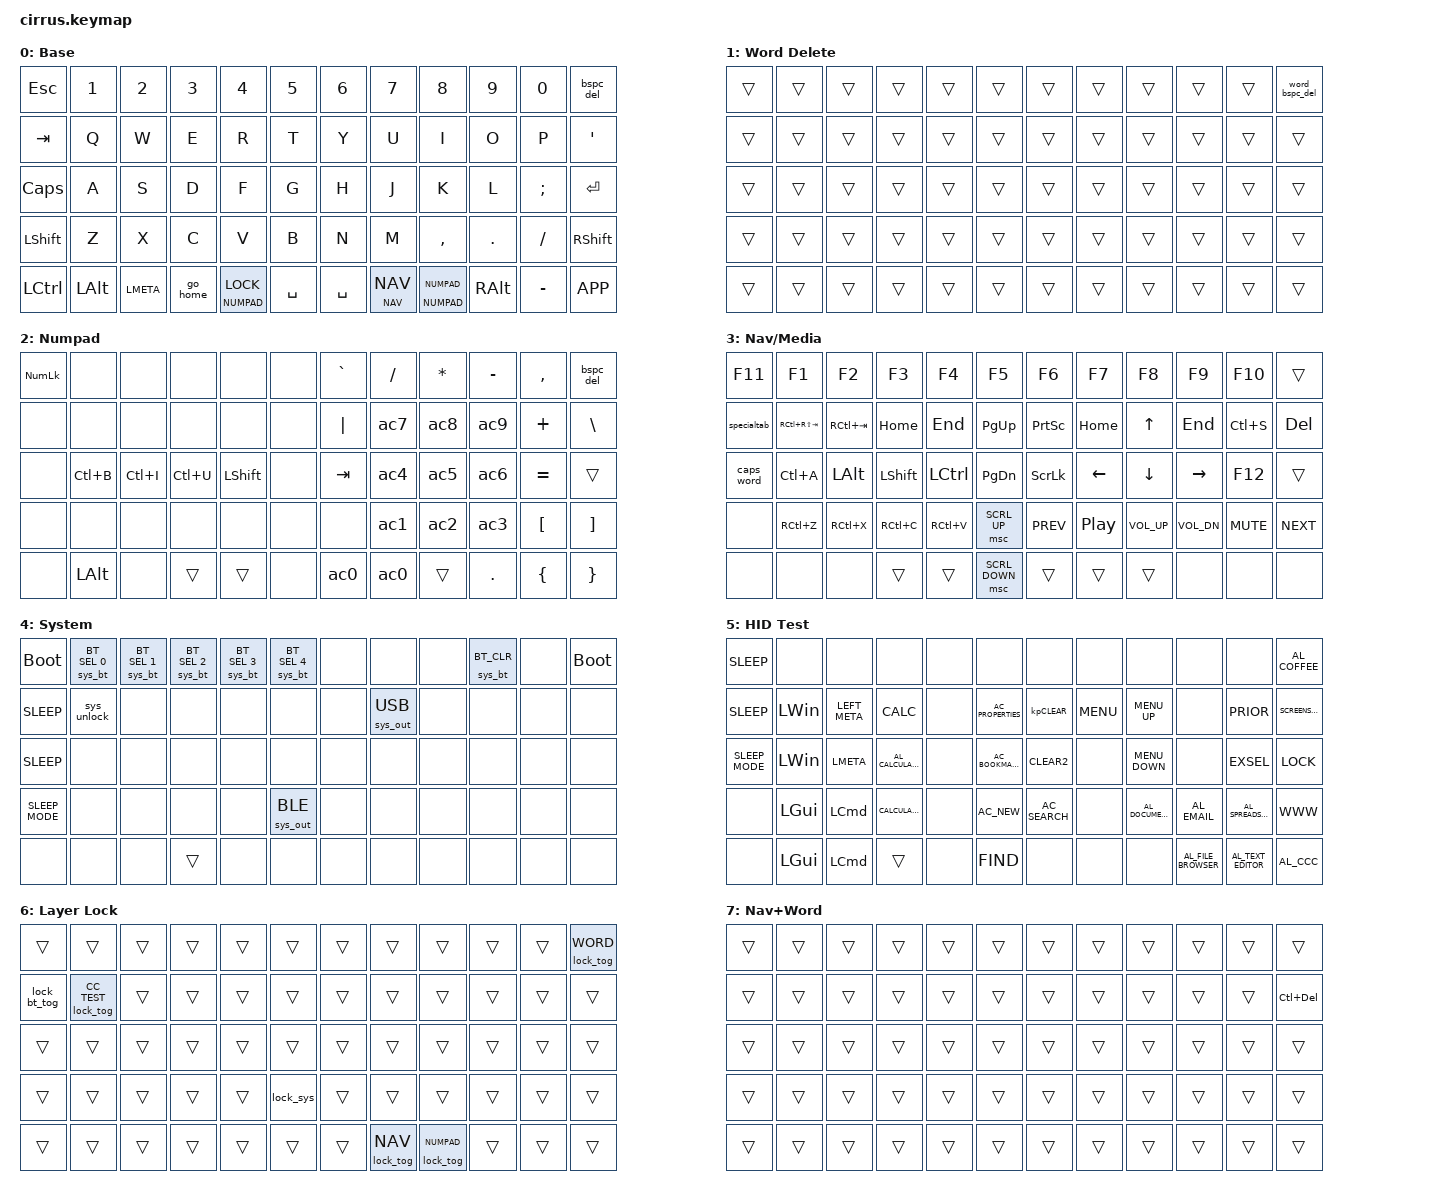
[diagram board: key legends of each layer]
#include <behaviors.dtsi>
#include <dt-bindings/zmk/bt.h>
#include <dt-bindings/zmk/keys.h>
#include <dt-bindings/zmk/outputs.h>
#include <dt-bindings/zmk/pointing.h>

// Layer numbers, by name. Use these names (not raw numbers) in bindings below,
// so adding or reordering layers can't silently break a key.
// Higher numbers sit "on top": their keys win over lower layers.
#define BASE      0
#define WORD      1   // word-delete mode (toggled on/off; sits just above Base)
#define NUMPAD    2
#define NAV       3
#define SYS       4
#define CC_TEST   5
#define LOCK      6
#define NAV_WORD  7   // turns on automatically when Nav + Word are both on

// Numpad digit that types a normal digit, but a KEYPAD digit while Alt is held, so Windows
// Alt codes work (hold Alt, type e.g. 0176, let go of Alt: °). Alt stays held (keep-mods).
// (MOD_MORPH_0 holds the "#binding-cells" line: a "#" can't appear directly inside ALT_CODE_DIGIT)
#define MOD_MORPH_0 compatible = "zmk,behavior-mod-morph"; #binding-cells = <0>
#define ALT_CODE_DIGIT(node, n) \
    node: node { \
        MOD_MORPH_0; \
        display-name = "Digit (Alt: keypad)"; \
        bindings = <&kp N##n>, <&kp KP_N##n>; \
        mods = <(MOD_LALT|MOD_RALT)>; \
        keep-mods = <(MOD_LALT|MOD_RALT)>; \
    };

/ {
    macros {
        // Hold Alt and tap Tab (Alt+Tab window switcher); Alt is released when you let go
        specialtab: specialtab {
            display-name = "Alt-Tab Hold";
            compatible = "zmk,behavior-macro";
            #binding-cells = <0>;
            bindings =
                <&macro_press>,
                <&kp LEFT_ALT>,
                <&macro_tap>,
                <&kp LA(TAB)>,
                <&macro_pause_for_release>,
                <&macro_release>,
                <&kp LEFT_ALT>;
        };

        // "Go home": turn off every locked layer and return to normal typing,
        // but leave word-delete mode as it was.
        go_home: go_home {
            display-name = "Go Home";
            compatible = "zmk,behavior-macro";
            #binding-cells = <0>;
            wait-ms = <0>;
            tap-ms = <0>;
            bindings = <&macro_tap &tog_off NUMPAD &tog_off NAV &tog_off SYS &tog_off CC_TEST &tog_off LOCK>;
        };

        // ---- Layer Lock actions ----
        // A sticky layer only ends when a real character is typed, so a layer toggle
        // pressed on Layer Lock would leave Layer Lock hanging around for a second.
        // These macros do their job and then end Layer Lock right away.

        // Toggle a layer on/off, then leave Layer Lock. Usage: &lock_tog WORD
        lock_tog: lock_toggle_layer {
            display-name = "Lock: Toggle Layer";
            compatible = "zmk,behavior-macro-one-param";
            #binding-cells = <1>;
            wait-ms = <0>;
            tap-ms = <0>;
            bindings
                = <&macro_param_1to1>
                , <&macro_tap &tog MACRO_PLACEHOLDER>
                , <&macro_tap &tog_off LOCK>
                ;
        };

        // Leave Layer Lock and open the System layer for ONE action (5 s timeout)
        lock_sys: lock_system_once {
            display-name = "Lock: System Once";
            compatible = "zmk,behavior-macro";
            #binding-cells = <0>;
            wait-ms = <0>;
            tap-ms = <0>;
            bindings = <&macro_tap &tog_off LOCK &sl_sys SYS>;
        };

        // Switch between Bluetooth profiles 1 and 2 (numbered 0 and 1 in ZMK), then leave Layer Lock
        lock_bt_tog: lock_bt_toggle {
            display-name = "Lock: BT 1/2 Toggle";
            compatible = "zmk,behavior-macro";
            #binding-cells = <0>;
            wait-ms = <0>;
            tap-ms = <0>;
            bindings = <&macro_tap &bt_tog01 &tog_off LOCK>;
        };

        // ---- System layer actions: do the action, then close the System layer ----

        // Usage: &sys_bt BT_SEL 0   or   &sys_bt BT_CLR
        sys_bt: system_bluetooth {
            display-name = "System: Bluetooth";
            compatible = "zmk,behavior-macro-two-param";
            #binding-cells = <2>;
            wait-ms = <0>;
            tap-ms = <0>;
            bindings
                = <&macro_param_1to1>
                , <&macro_param_2to2>
                , <&macro_tap &bt MACRO_PLACEHOLDER MACRO_PLACEHOLDER>
                , <&macro_tap &tog_off SYS>
                ;
        };

        // Usage: &sys_out OUT_USB
        sys_out: system_output {
            display-name = "System: Output";
            compatible = "zmk,behavior-macro-one-param";
            #binding-cells = <1>;
            wait-ms = <0>;
            tap-ms = <0>;
            bindings
                = <&macro_param_1to1>
                , <&macro_tap &out MACRO_PLACEHOLDER>
                , <&macro_tap &tog_off SYS>
                ;
        };

        sys_unlock: system_studio_unlock {
            display-name = "System: Studio Unlock";
            compatible = "zmk,behavior-macro";
            #binding-cells = <0>;
            wait-ms = <0>;
            tap-ms = <0>;
            bindings = <&macro_tap &studio_unlock &tog_off SYS>;
        };
    };

    behaviors {
        // Hold = layer active while held (&mo). Tap = toggle the layer on/off (&tog).
        layer_mo_lock: layer_mo_lock {
            display-name = "Hold Layer / Tap Lock";
            compatible = "zmk,behavior-hold-tap";
            #binding-cells = <2>;
            bindings = <&mo>, <&tog>;
            tapping-term-ms = <200>;
        };

        // Hold = layer active while held (&mo). Tap = one-shot layer (&sl).
        // Used on the left-thumb key: hold for Numpad, tap for Layer Lock.
        layer_mo_sticky: layer_mo_sticky {
            display-name = "Hold Layer / Tap Sticky";
            compatible = "zmk,behavior-hold-tap";
            #binding-cells = <2>;
            bindings = <&mo>, <&sl>;
            tapping-term-ms = <200>;
        };

        // One-shot System layer: lasts for one keypress, or 5 seconds if nothing is pressed.
        sl_sys: sticky_layer_system {
            display-name = "Sticky Layer (5 s)";
            compatible = "zmk,behavior-sticky-key";
            #binding-cells = <1>;
            release-after-ms = <5000>;
            bindings = <&mo>;
            quick-release;
        };

        // Custom behavior (src/behaviors/): flip between Bluetooth profiles 0 and 1.
        bt_tog01: bt_profile_toggle {
            display-name = "BT 1/2 Toggle";
            compatible = "zmk,behavior-bt-profile-toggle";
            #binding-cells = <0>;
            profile-a = <0>;
            profile-b = <1>;
        };

        // Turns a layer off (never on). Used by the "go home" key.
        tog_off: toggle_layer_off_only {
            compatible = "zmk,behavior-toggle-layer";
            #binding-cells = <1>;
            display-name = "Toggle Layer Off";
            toggle-mode = "off";
        };

        // Backspace; with Shift held it sends Delete instead (Shift is not passed on)
        bspc_del: backspace_delete {
            display-name = "Bksp (Shift: Del)";
            compatible = "zmk,behavior-mod-morph";
            #binding-cells = <0>;
            bindings = <&kp BSPC>, <&kp DEL>;
            mods = <(MOD_LSFT|MOD_RSFT)>;
        };

        // Numpad digits 0-9 (see ALT_CODE_DIGIT at the top)
        ALT_CODE_DIGIT(ac0, 0) ALT_CODE_DIGIT(ac1, 1) ALT_CODE_DIGIT(ac2, 2) ALT_CODE_DIGIT(ac3, 3)
        ALT_CODE_DIGIT(ac4, 4) ALT_CODE_DIGIT(ac5, 5) ALT_CODE_DIGIT(ac6, 6) ALT_CODE_DIGIT(ac7, 7)
        ALT_CODE_DIGIT(ac8, 8) ALT_CODE_DIGIT(ac9, 9)

        // Word-delete version: Ctrl+Backspace; with Shift held, Ctrl+Delete
        word_bspc_del: word_backspace_delete {
            display-name = "Word Bksp (Shift: Del)";
            compatible = "zmk,behavior-mod-morph";
            #binding-cells = <0>;
            bindings = <&kp LC(BSPC)>, <&kp LC(DEL)>;
            mods = <(MOD_LSFT|MOD_RSFT)>;
        };
    };

    // Nav + Word both on => Nav+Word layer on (makes Nav's Delete key delete whole words)
    conditional_layers {
        compatible = "zmk,conditional-layers";
        nav_word {
            if-layers = <WORD NAV>;
            then-layer = <NAV_WORD>;
        };
    };

    keymap {
        compatible = "zmk,keymap";

        default_layer {
            display-name = "Base";
            bindings = <
&kp ESCAPE    &kp N1    &kp N2     &kp N3    &kp N4                           &kp N5       &kp N6     &kp N7                   &kp N8                         &kp N9         &kp N0     &bspc_del
&kp TAB       &kp Q     &kp W      &kp E     &kp R                            &kp T        &kp Y      &kp U                    &kp I                          &kp O          &kp P      &kp APOS
&kp CAPSLOCK  &kp A     &kp S      &kp D     &kp F                            &kp G        &kp H      &kp J                    &kp K                          &kp L          &kp SEMI   &kp RET
&kp LSHFT     &kp Z     &kp X      &kp C     &kp V                            &kp B        &kp N      &kp M                    &kp COMMA                      &kp DOT        &kp FSLH   &kp RIGHT_SHIFT
&kp LCTRL     &kp LALT  &kp LMETA  &go_home  &layer_mo_sticky NUMPAD LOCK     &kp SPACE    &kp SPACE  &layer_mo_lock NAV NAV   &layer_mo_lock NUMPAD NUMPAD   &kp RIGHT_ALT  &kp MINUS  &kp K_APP
            >;
        };

        // Word-delete mode: Backspace deletes the previous word (Ctrl+Backspace),
        // Shift+Backspace deletes the next word. Toggle: Layer Lock, then Backspace.
        word_delete {
            display-name = "Word Delete";
            bindings = <
&trans  &trans  &trans  &trans  &trans  &trans    &trans  &trans  &trans  &trans  &trans  &word_bspc_del
&trans  &trans  &trans  &trans  &trans  &trans    &trans  &trans  &trans  &trans  &trans  &trans
&trans  &trans  &trans  &trans  &trans  &trans    &trans  &trans  &trans  &trans  &trans  &trans
&trans  &trans  &trans  &trans  &trans  &trans    &trans  &trans  &trans  &trans  &trans  &trans
&trans  &trans  &trans  &trans  &trans  &trans    &trans  &trans  &trans  &trans  &trans  &trans
            >;
        };

        // Hold the left-thumb key (next to left space) or the 2nd key right of right space.
        // Backspace here always deletes one character, even in word mode.
        // Left home row: A/S/D = Bold / Italic / Underline (Ctrl+B / Ctrl+I / Ctrl+U)
        // Alt in its usual spot + digits that switch to keypad digits while Alt is held = Alt codes.
        // Num Lock (Esc spot): Alt codes need it on; if a code moves the cursor instead, tap it.
        num_pad {
            display-name = "Numpad";
            bindings = <
&kp KP_NUMLOCK  &none     &none      &none      &none      &none        &kp GRAVE  &kp SLASH  &kp ASTRK  &kp MINUS   &kp COMMA         &bspc_del
&none  &none      &none      &none      &none      &none        &kp PIPE   &ac7       &ac8       &ac9        &kp PLUS          &kp BSLH
&none  &kp LC(B)  &kp LC(I)  &kp LC(U)  &kp LSHFT  &none        &kp TAB    &ac4       &ac5       &ac6        &kp EQUAL         &trans
&none  &none  &none  &none  &none      &none        &none      &ac1       &ac2       &ac3        &kp LEFT_BRACKET  &kp RIGHT_BRACKET
&none  &kp LALT  &none  &trans &trans  &none        &ac0       &ac0       &trans     &kp PERIOD  &kp LEFT_BRACE    &kp RIGHT_BRACE
            >;
        };

        arrows_media {
            display-name = "Nav/Media";
            bindings = <
&kp F11      &kp F1           &kp F2       &kp F3     &kp F4     &kp F5            &kp F6           &kp F7    &kp F8        &kp F9        &kp F10     &trans
&specialtab  &kp RC(RS(TAB))  &kp RC(TAB)  &kp HOME   &kp END    &kp PAGE_UP       &kp PRINTSCREEN  &kp HOME  &kp UP        &kp END       &kp LC(S)   &kp DEL
&caps_word   &kp LC(A)        &kp LALT     &kp LSHFT  &kp LCTRL  &kp PAGE_DOWN     &kp SCROLLLOCK   &kp LEFT  &kp DOWN      &kp RIGHT     &kp F12     &trans
&none        &kp RC(Z)        &kp RC(X)    &kp RC(C)  &kp RC(V)  &msc SCRL_UP      &kp C_PREV       &kp C_PP  &kp C_VOL_UP  &kp C_VOL_DN  &kp C_MUTE  &kp C_NEXT
&none        &none            &none        &trans     &trans     &msc SCRL_DOWN    &trans           &trans    &trans        &none         &none       &none
            >;
        };

        // Reached with Layer Lock, then B. ONE action only: after any key (or 5 s), it closes itself.
        // "Forget ALL devices" was removed; flash settings_reset if you ever truly need that.
        system {
            display-name = "System";
            bindings = <
&bootloader       &sys_bt BT_SEL 0  &sys_bt BT_SEL 1  &sys_bt BT_SEL 2  &sys_bt BT_SEL 3  &sys_bt BT_SEL 4    &none  &none             &none  &sys_bt BT_CLR  &none  &bootloader
&kp K_SLEEP       &sys_unlock       &none             &none             &none             &none                &none  &sys_out OUT_USB  &none  &none           &none  &none
&kp C_SLEEP       &none             &none             &none             &none             &none                &none  &none             &none  &none           &none  &none
&kp C_SLEEP_MODE  &none             &none             &none             &none             &sys_out OUT_BLE     &none  &none             &none  &none           &none  &none
&none             &none             &none             &trans            &none             &none                &none  &none             &none  &none           &none  &none
            >;
        };

        // TESTING ONLY: used to check which media/system keycodes the computer responds to.
        consumer_control_testing {
            display-name = "HID Test";
            bindings = <
&kp K_SLEEP       &none         &none             &none                &none  &none                  &none            &none       &none               &none                  &none                 &kp C_AL_COFFEE
&kp C_SLEEP       &kp LWIN      &kp LEFT_META     &kp K_CALC           &none  &kp C_AC_PROPERTIES    &kp KP_CLEAR     &kp C_MENU  &kp C_MENU_UP       &none                  &kp PRIOR             &kp K_SCREENSAVER
&kp C_SLEEP_MODE  &kp LEFT_WIN  &kp LMETA         &kp C_AL_CALCULATOR  &none  &kp C_AC_BOOKMARKS     &kp CLEAR2       &none       &kp C_MENU_DOWN     &none                  &kp EXSEL             &kp K_LOCK
&none             &kp LEFT_GUI  &kp LEFT_COMMAND  &kp K_CALCULATOR     &none  &kp C_AC_NEW           &kp C_AC_SEARCH  &none       &kp C_AL_DOCUMENTS  &kp C_AL_EMAIL         &kp C_AL_SPREADSHEET  &kp K_WWW
&none             &kp LGUI      &kp LCMD          &trans               &none  &kp K_FIND             &none            &none       &none               &kp C_AL_FILE_BROWSER  &kp C_AL_TEXT_EDITOR  &kp C_AL_CCC
            >;
        };

        // Reached by tapping the left-thumb key (next to left space): applies to the NEXT key only,
        // and every action here ends Layer Lock immediately.
        //   Backspace = word-delete mode on/off    Tab = switch Bluetooth device 1 <-> 2
        //   Q = HID Test    B = System (one action)
        //   Nav / Numpad keys (right of right space) = lock that layer on
        // Any other key types normally.
        layer_lock {
            display-name = "Layer Lock";
            bindings = <
&trans         &trans             &trans  &trans  &trans  &trans        &trans  &trans             &trans                &trans  &trans  &lock_tog WORD
&lock_bt_tog   &lock_tog CC_TEST  &trans  &trans  &trans  &trans        &trans  &trans             &trans                &trans  &trans  &trans
&trans         &trans             &trans  &trans  &trans  &trans        &trans  &trans             &trans                &trans  &trans  &trans
&trans         &trans             &trans  &trans  &trans  &lock_sys     &trans  &trans             &trans                &trans  &trans  &trans
&trans         &trans             &trans  &trans  &trans  &trans        &trans  &lock_tog NAV      &lock_tog NUMPAD      &trans  &trans  &trans
            >;
        };

        // Turns on by itself when Nav and Word Delete are both on:
        // Nav's Delete key deletes the next word (Ctrl+Delete).
        nav_word_delete {
            display-name = "Nav+Word";
            bindings = <
&trans  &trans  &trans  &trans  &trans  &trans    &trans  &trans  &trans  &trans  &trans  &trans
&trans  &trans  &trans  &trans  &trans  &trans    &trans  &trans  &trans  &trans  &trans  &kp LC(DEL)
&trans  &trans  &trans  &trans  &trans  &trans    &trans  &trans  &trans  &trans  &trans  &trans
&trans  &trans  &trans  &trans  &trans  &trans    &trans  &trans  &trans  &trans  &trans  &trans
&trans  &trans  &trans  &trans  &trans  &trans    &trans  &trans  &trans  &trans  &trans  &trans
            >;
        };

        // Spare layers: hidden in normal use, but available to fill in from ZMK Studio.
        extra_1 {
            status = "reserved";
        };

        extra_2 {
            status = "reserved";
        };
    };
};
